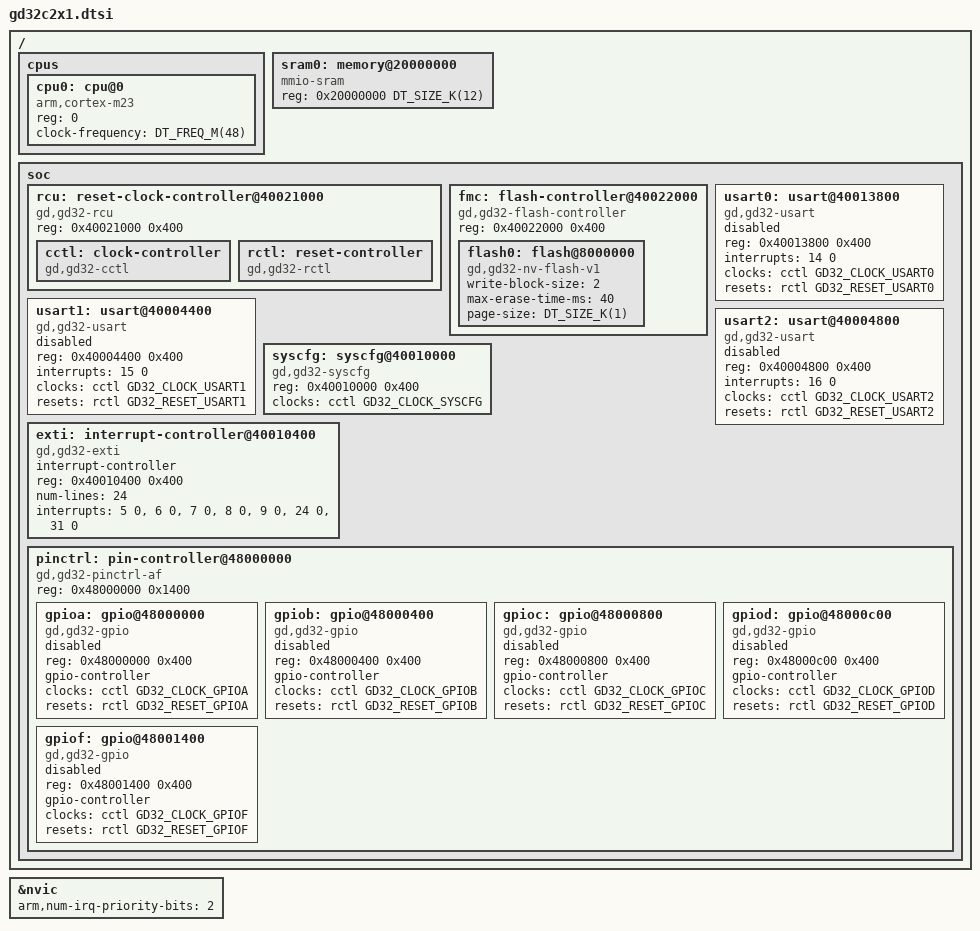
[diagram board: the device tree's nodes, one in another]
/*
 * Copyright (c) 2026 GigaDevice Semiconductor Inc.
 *
 * SPDX-License-Identifier: Apache-2.0
 */

#include <freq.h>
#include <mem.h>
#include <arm/armv8-m.dtsi>
#include <zephyr/dt-bindings/adc/adc.h>
#include <zephyr/dt-bindings/gpio/gpio.h>
#include <zephyr/dt-bindings/i2c/i2c.h>
#include <zephyr/dt-bindings/pwm/pwm.h>
#include <zephyr/dt-bindings/clock/gd32c2x1-clocks.h>
#include <zephyr/dt-bindings/reset/gd32c2x1.h>

/ {
	cpus {
		#address-cells = <1>;
		#size-cells = <0>;

		cpu0: cpu@0 {
			compatible = "arm,cortex-m23";
			reg = <0>;
			#address-cells = <1>;
			#size-cells = <1>;
			clock-frequency = <DT_FREQ_M(48)>;
		};
	};

	sram0: memory@20000000 {
		compatible = "mmio-sram";
		reg = <0x20000000 DT_SIZE_K(12)>;
	};

	soc {
		rcu: reset-clock-controller@40021000 {
			compatible = "gd,gd32-rcu";
			reg = <0x40021000 0x400>;
			status = "okay";

			cctl: clock-controller {
				compatible = "gd,gd32-cctl";
				#clock-cells = <1>;
				status = "okay";
			};

			rctl: reset-controller {
				compatible = "gd,gd32-rctl";
				#reset-cells = <1>;
				status = "okay";
			};
		};

		fmc: flash-controller@40022000 {
			compatible = "gd,gd32-flash-controller";
			reg = <0x40022000 0x400>;

			#address-cells = <1>;
			#size-cells = <1>;
			ranges;

			flash0: flash@8000000 {
				compatible = "gd,gd32-nv-flash-v1", "soc-nv-flash";
				write-block-size = <2>;
				max-erase-time-ms = <40>;
				page-size = <DT_SIZE_K(1)>;
			};
		};

		usart0: usart@40013800 {
			compatible = "gd,gd32-usart";
			reg = <0x40013800 0x400>;
			interrupts = <14 0>;
			clocks = <&cctl GD32_CLOCK_USART0>;
			resets = <&rctl GD32_RESET_USART0>;
			status = "disabled";
		};

		usart1: usart@40004400 {
			compatible = "gd,gd32-usart";
			reg = <0x40004400 0x400>;
			interrupts = <15 0>;
			clocks = <&cctl GD32_CLOCK_USART1>;
			resets = <&rctl GD32_RESET_USART1>;
			status = "disabled";
		};

		usart2: usart@40004800 {
			compatible = "gd,gd32-usart";
			reg = <0x40004800 0x400>;
			interrupts = <16 0>;
			clocks = <&cctl GD32_CLOCK_USART2>;
			resets = <&rctl GD32_RESET_USART2>;
			status = "disabled";
		};

		syscfg: syscfg@40010000 {
			compatible = "gd,gd32-syscfg";
			reg = <0x40010000 0x400>;
			clocks = <&cctl GD32_CLOCK_SYSCFG>;
		};

		exti: interrupt-controller@40010400 {
			compatible = "gd,gd32-exti";
			interrupt-controller;
			#interrupt-cells = <1>;
			#address-cells = <0>;
			reg = <0x40010400 0x400>;
			num-lines = <24>;
			interrupts = <5 0>, <6 0>, <7 0>, <8 0>,
				     <9 0>, <24 0>, <31 0>;
			interrupt-names = "line0", "line1", "line2", "line3",
					  "line4", "line5-9", "line10-15";
			status = "okay";
		};

		pinctrl: pin-controller@48000000 {
			compatible = "gd,gd32-pinctrl-af";
			reg = <0x48000000 0x1400>;
			#address-cells = <1>;
			#size-cells = <1>;
			status = "okay";

			gpioa: gpio@48000000 {
				compatible = "gd,gd32-gpio";
				reg = <0x48000000 0x400>;
				#gpio-cells = <2>;
				gpio-controller;
				clocks = <&cctl GD32_CLOCK_GPIOA>;
				resets = <&rctl GD32_RESET_GPIOA>;
				status = "disabled";
			};

			gpiob: gpio@48000400 {
				compatible = "gd,gd32-gpio";
				reg = <0x48000400 0x400>;
				#gpio-cells = <2>;
				gpio-controller;
				clocks = <&cctl GD32_CLOCK_GPIOB>;
				resets = <&rctl GD32_RESET_GPIOB>;
				status = "disabled";
			};

			gpioc: gpio@48000800 {
				compatible = "gd,gd32-gpio";
				reg = <0x48000800 0x400>;
				#gpio-cells = <2>;
				gpio-controller;
				clocks = <&cctl GD32_CLOCK_GPIOC>;
				resets = <&rctl GD32_RESET_GPIOC>;
				status = "disabled";
			};

			gpiod: gpio@48000c00 {
				compatible = "gd,gd32-gpio";
				reg = <0x48000c00 0x400>;
				#gpio-cells = <2>;
				gpio-controller;
				clocks = <&cctl GD32_CLOCK_GPIOD>;
				resets = <&rctl GD32_RESET_GPIOD>;
				status = "disabled";
			};

			gpiof: gpio@48001400 {
				compatible = "gd,gd32-gpio";
				reg = <0x48001400 0x400>;
				#gpio-cells = <2>;
				gpio-controller;
				clocks = <&cctl GD32_CLOCK_GPIOF>;
				resets = <&rctl GD32_RESET_GPIOF>;
				status = "disabled";
			};
		};
	};
};

&nvic {
	arm,num-irq-priority-bits = <2>;
};
